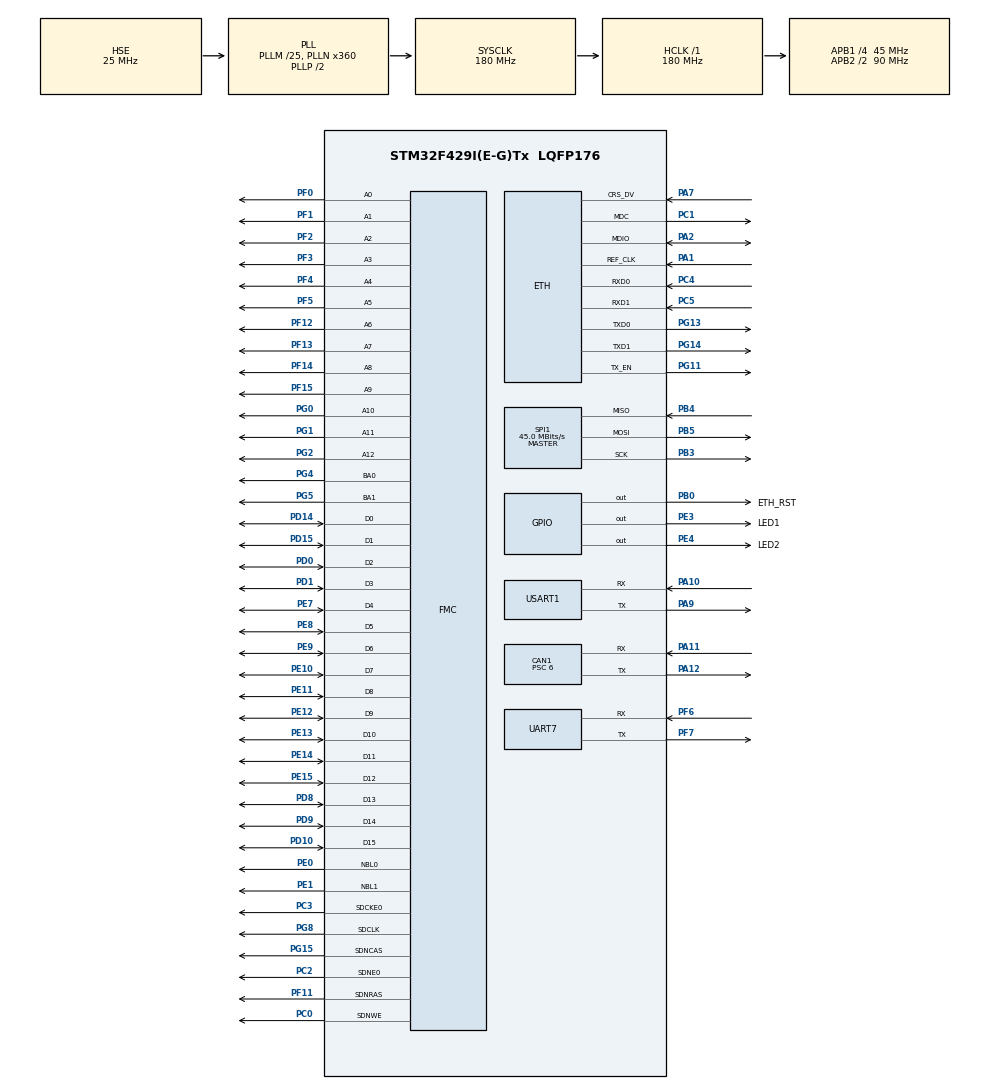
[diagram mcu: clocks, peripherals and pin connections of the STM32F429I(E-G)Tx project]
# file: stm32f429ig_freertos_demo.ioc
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CAN1.BS1=CAN_BS1_9TQ
CAN1.BS2=CAN_BS2_5TQ
CAN1.CalculateTimeQuantum=133.33333333333331
CAN1.NART=ENABLE
CAN1.Prescaler=6
ETH.MediaInterface=ETH_MEDIA_INTERFACE_RMII
ETH.PHY_Name_RMII=userPHY
ETH.PHY_User_Name=LAN8720A
ETH.PhyAddress=0
FMC.CASLatency1=FMC_SDRAM_CAS_LATENCY_3
FMC.ColumnBitsNumber1=FMC_SDRAM_COLUMN_BITS_NUM_9
FMC.ExitSelfRefreshDelay1=7
FMC.LoadToActiveDelay1=2
FMC.RCDDelay1=2
FMC.RPDelay1=2
FMC.ReadBurst1=FMC_SDRAM_RBURST_ENABLE
FMC.ReadPipeDelay1=FMC_SDRAM_RPIPE_DELAY_1
FMC.RowCycleDelay1=7
FMC.SDClockPeriod1=FMC_SDRAM_CLOCK_PERIOD_2
FMC.SelfRefreshTime1=4
FMC.WriteRecoveryTime1=4
FREERTOS.HEAP_NUMBER=5
FREERTOS.Tasks01=defaultTask,0,128,StartDefaultTask,Default,NULL,Dynamic,NULL,NULL
FREERTOS.configTOTAL_HEAP_SIZE=65536
LWIP.GATEWAY_ADDRESS=192.168.000.001
LWIP.IP_ADDRESS=192.168.000.123
LWIP.LWIP_DHCP=0
LWIP.NETMASK_ADDRESS=255.255.255.000
LWIP.Version=v2.1.2_Cube
Mcu.Family=STM32F4
Mcu.Name=STM32F429I(E-G)Tx
Mcu.Package=LQFP176
NVIC.CAN1_RX0_IRQn=true\:5\:0\:false\:false\:true\:true\:true\:true
NVIC.CAN1_RX1_IRQn=true\:5\:0\:false\:false\:true\:true\:true\:true
NVIC.CAN1_SCE_IRQn=true\:5\:0\:false\:false\:true\:true\:true\:true
NVIC.CAN1_TX_IRQn=true\:5\:0\:false\:false\:true\:true\:true\:true
NVIC.ETH_IRQn=true\:5\:0\:false\:false\:true\:true\:false\:true
NVIC.PriorityGroup=NVIC_PRIORITYGROUP_4
NVIC.UART7_IRQn=true\:5\:0\:false\:false\:true\:true\:true\:true
NVIC.USART1_IRQn=true\:5\:0\:false\:false\:true\:true\:true\:true
PA1.Mode=RMII
PA1.Signal=ETH_REF_CLK
PA10.Mode=Asynchronous
PA10.Signal=USART1_RX
PA11.GPIO_PuPd=GPIO_NOPULL
PA11.Mode=Master
PA11.Signal=CAN1_RX
PA12.GPIO_PuPd=GPIO_NOPULL
PA12.Mode=Master
PA12.Signal=CAN1_TX
PA13.Mode=Serial_Wire
PA13.Signal=SYS_JTMS-SWDIO
PA14.Mode=Serial_Wire
PA14.Signal=SYS_JTCK-SWCLK
PA2.Mode=RMII
PA2.Signal=ETH_MDIO
PA7.Mode=RMII
PA7.Signal=ETH_CRS_DV
PA9.Mode=Asynchronous
PA9.Signal=USART1_TX
PB0.GPIO_Label=ETH_RST
PB0.PinState=GPIO_PIN_SET
PB0.Signal=GPIO_Output
PB3.Mode=Full_Duplex_Master
PB3.Signal=SPI1_SCK
PB4.Mode=Full_Duplex_Master
PB4.Signal=SPI1_MISO
PB5.Mode=Full_Duplex_Master
PB5.Signal=SPI1_MOSI
PC0.Signal=FMC_SDNWE
PC1.Mode=RMII
PC1.Signal=ETH_MDC
PC2.Mode=SdramChipSelect1_1
PC2.Signal=FMC_SDNE0
PC3.Mode=SdramChipSelect1_1
PC3.Signal=FMC_SDCKE0
PC4.Mode=RMII
PC4.Signal=ETH_RXD0
PC5.Mode=RMII
PC5.Signal=ETH_RXD1
PD0.Signal=FMC_D2_DA2
PD1.Signal=FMC_D3_DA3
PD10.Signal=FMC_D15_DA15
PD14.Signal=FMC_D0_DA0
PD15.Signal=FMC_D1_DA1
PD8.Signal=FMC_D13_DA13
PD9.Signal=FMC_D14_DA14
PE0.Signal=FMC_NBL0
PE1.Signal=FMC_NBL1
PE10.Signal=FMC_D7_DA7
PE11.Signal=FMC_D8_DA8
PE12.Signal=FMC_D9_DA9
PE13.Signal=FMC_D10_DA10
PE14.Signal=FMC_D11_DA11
PE15.Signal=FMC_D12_DA12
PE3.GPIO_Label=LED1
PE3.Signal=GPIO_Output
PE4.GPIO_Label=LED2
PE4.Signal=GPIO_Output
PE7.Signal=FMC_D4_DA4
PE8.Signal=FMC_D5_DA5
PE9.Signal=FMC_D6_DA6
PF0.Signal=FMC_A0
PF1.Signal=FMC_A1
PF11.Signal=FMC_SDNRAS
PF12.Signal=FMC_A6
PF13.Signal=FMC_A7
PF14.Signal=FMC_A8
PF15.Signal=FMC_A9
PF2.Signal=FMC_A2
PF3.Signal=FMC_A3
PF4.Signal=FMC_A4
PF5.Signal=FMC_A5
PF6.Mode=Asynchronous
PF6.Signal=UART7_RX
PF7.Mode=Asynchronous
PF7.Signal=UART7_TX
PG0.Signal=FMC_A10
PG1.Signal=FMC_A11
PG11.Mode=RMII
PG11.Signal=ETH_TX_EN
PG13.Mode=RMII
PG13.Signal=ETH_TXD0
PG14.Mode=RMII
PG14.Signal=ETH_TXD1
PG15.Signal=FMC_SDNCAS
PG2.Signal=FMC_A12
PG4.Signal=FMC_A14_BA0
PG5.Signal=FMC_A15_BA1
PG8.Signal=FMC_SDCLK
PH0/OSC_IN.Mode=HSE-External-Oscillator
PH0/OSC_IN.Signal=RCC_OSC_IN
PH1/OSC_OUT.Mode=HSE-External-Oscillator
PH1/OSC_OUT.Signal=RCC_OSC_OUT
ProjectManager.HeapSize=0x800
ProjectManager.StackSize=0x800
ProjectManager.TargetToolchain=STM32CubeIDE
RCC.48MHZClocksFreq_Value=90000000
RCC.AHBFreq_Value=180000000
RCC.APB1CLKDivider=RCC_HCLK_DIV4
RCC.APB1Freq_Value=45000000
RCC.APB1TimFreq_Value=90000000
RCC.APB2CLKDivider=RCC_HCLK_DIV2
RCC.APB2Freq_Value=90000000
RCC.APB2TimFreq_Value=180000000
RCC.CortexFreq_Value=180000000
RCC.HCLKFreq_Value=180000000
RCC.HSE_VALUE=25000000
RCC.HSI_VALUE=16000000
RCC.LSE_VALUE=32768
RCC.PLLM=25
RCC.PLLN=360
RCC.PLLSourceVirtual=RCC_PLLSOURCE_HSE
RCC.SYSCLKFreq_VALUE=180000000
RCC.SYSCLKSource=RCC_SYSCLKSOURCE_PLLCLK
RCC.VCOOutputFreq_Value=360000000
SH.FMC_A0.0=FMC_A0,13b-sda1
SH.FMC_A1.0=FMC_A1,13b-sda1
SH.FMC_A10.0=FMC_A10,13b-sda1
SH.FMC_A11.0=FMC_A11,13b-sda1
SH.FMC_A12.0=FMC_A12,13b-sda1
SH.FMC_A14_BA0.0=FMC_BA0,FourSdramBanks1
SH.FMC_A15_BA1.0=FMC_BA1,FourSdramBanks1
SH.FMC_A2.0=FMC_A2,13b-sda1
SH.FMC_A3.0=FMC_A3,13b-sda1
SH.FMC_A4.0=FMC_A4,13b-sda1
SH.FMC_A5.0=FMC_A5,13b-sda1
SH.FMC_A6.0=FMC_A6,13b-sda1
SH.FMC_A7.0=FMC_A7,13b-sda1
SH.FMC_A8.0=FMC_A8,13b-sda1
SH.FMC_A9.0=FMC_A9,13b-sda1
SH.FMC_D0_DA0.0=FMC_D0,sd-16b-d1
SH.FMC_D10_DA10.0=FMC_D10,sd-16b-d1
SH.FMC_D11_DA11.0=FMC_D11,sd-16b-d1
SH.FMC_D12_DA12.0=FMC_D12,sd-16b-d1
SH.FMC_D13_DA13.0=FMC_D13,sd-16b-d1
SH.FMC_D14_DA14.0=FMC_D14,sd-16b-d1
SH.FMC_D15_DA15.0=FMC_D15,sd-16b-d1
SH.FMC_D1_DA1.0=FMC_D1,sd-16b-d1
SH.FMC_D2_DA2.0=FMC_D2,sd-16b-d1
SH.FMC_D3_DA3.0=FMC_D3,sd-16b-d1
SH.FMC_D4_DA4.0=FMC_D4,sd-16b-d1
SH.FMC_D5_DA5.0=FMC_D5,sd-16b-d1
SH.FMC_D6_DA6.0=FMC_D6,sd-16b-d1
SH.FMC_D7_DA7.0=FMC_D7,sd-16b-d1
SH.FMC_D8_DA8.0=FMC_D8,sd-16b-d1
SH.FMC_D9_DA9.0=FMC_D9,sd-16b-d1
SH.FMC_NBL0.0=FMC_NBL0,Sd2ByteEnable1
SH.FMC_NBL1.0=FMC_NBL1,Sd2ByteEnable1
SH.FMC_SDCLK.0=FMC_SDCLK,13b-sda1
SH.FMC_SDNCAS.0=FMC_SDNCAS,13b-sda1
SH.FMC_SDNRAS.0=FMC_SDNRAS,13b-sda1
SH.FMC_SDNWE.0=FMC_SDNWE,13b-sda1
SPI1.CalculateBaudRate=45.0 MBits/s
SPI1.Direction=SPI_DIRECTION_2LINES
SPI1.Mode=SPI_MODE_MASTER
SPI1.VirtualType=VM_MASTER
UART7.VirtualMode=Asynchronous
USART1.VirtualMode=VM_ASYNC
VP_FREERTOS_VS_CMSIS_V1.Mode=CMSIS_V1
VP_LWIP_VS_Enabled.Mode=Enabled
board=custom

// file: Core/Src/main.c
/* USER CODE BEGIN Header */
/**
  ******************************************************************************
  * @file           : main.c
  * @brief          : Main program body
  ******************************************************************************
  * @attention
  *
  * <h2><center>&copy; Copyright (c) 2020 STMicroelectronics.
  * All rights reserved.</center></h2>
  *
  * This software component is licensed by ST under Ultimate Liberty license
  * SLA0044, the "License"; You may not use this file except in compliance with
  * the License. You may obtain a copy of the License at:
  *                             www.st.com/SLA0044
  *
  ******************************************************************************
  */
/* USER CODE END Header */

#include "main.h"
#include "cmsis_os.h"
#include "can.h"
#include "lwip.h"
#include "spi.h"
#include "usart.h"
#include "gpio.h"
#include "fmc.h"

void SystemClock_Config(void);
void MX_FREERTOS_Init(void);

int main(void)
{

  /* MCU Configuration--------------------------------------------------------*/

  /* Reset of all peripherals, Initializes the Flash interface and the Systick. */
  HAL_Init();

  /* Configure the system clock */
  SystemClock_Config();

  /* Initialize all configured peripherals */
  MX_GPIO_Init();
  MX_CAN1_Init();
  MX_UART7_Init();
  MX_USART1_UART_Init();
  MX_FMC_Init();
  MX_SPI1_Init();
  /* USER CODE BEGIN 2 */
  SDRAM_Init();
  heap_init();
  /* USER CODE END 2 */

  /* Call init function for freertos objects (in freertos.c) */
  MX_FREERTOS_Init();
  /* Start scheduler */
  osKernelStart();

  /* We should never get here as control is now taken by the scheduler */
  /* Infinite loop */
  while (1)
  {

  }
}

void SystemClock_Config(void)
{
  RCC_OscInitTypeDef RCC_OscInitStruct = {0};
  RCC_ClkInitTypeDef RCC_ClkInitStruct = {0};

  /** Configure the main internal regulator output voltage
  */
  __HAL_RCC_PWR_CLK_ENABLE();
  __HAL_PWR_VOLTAGESCALING_CONFIG(PWR_REGULATOR_VOLTAGE_SCALE1);
  /** Initializes the CPU, AHB and APB busses clocks
  */
  RCC_OscInitStruct.OscillatorType = RCC_OSCILLATORTYPE_HSE;
  RCC_OscInitStruct.HSEState = RCC_HSE_ON;
  RCC_OscInitStruct.PLL.PLLState = RCC_PLL_ON;
  RCC_OscInitStruct.PLL.PLLSource = RCC_PLLSOURCE_HSE;
  RCC_OscInitStruct.PLL.PLLM = 25;
  RCC_OscInitStruct.PLL.PLLN = 360;
  RCC_OscInitStruct.PLL.PLLP = RCC_PLLP_DIV2;
  RCC_OscInitStruct.PLL.PLLQ = 4;
  if (HAL_RCC_OscConfig(&RCC_OscInitStruct) != HAL_OK)
  {
    Error_Handler();
  }
  /** Activate the Over-Drive mode
  */
  if (HAL_PWREx_EnableOverDrive() != HAL_OK)
  {
    Error_Handler();
  }
  /** Initializes the CPU, AHB and APB busses clocks
  */
  RCC_ClkInitStruct.ClockType = RCC_CLOCKTYPE_HCLK|RCC_CLOCKTYPE_SYSCLK
                              |RCC_CLOCKTYPE_PCLK1|RCC_CLOCKTYPE_PCLK2;
  RCC_ClkInitStruct.SYSCLKSource = RCC_SYSCLKSOURCE_PLLCLK;
  RCC_ClkInitStruct.AHBCLKDivider = RCC_SYSCLK_DIV1;
  RCC_ClkInitStruct.APB1CLKDivider = RCC_HCLK_DIV4;
  RCC_ClkInitStruct.APB2CLKDivider = RCC_HCLK_DIV2;

  if (HAL_RCC_ClockConfig(&RCC_ClkInitStruct, FLASH_LATENCY_5) != HAL_OK)
  {
    Error_Handler();
  }
}

void Error_Handler(void)
{
}

/************************ (C) COPYRIGHT STMicroelectronics *****END OF FILE****/

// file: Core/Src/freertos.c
/* USER CODE BEGIN Header */
/**
  ******************************************************************************
  * File Name          : freertos.c
  * Description        : Code for freertos applications
  ******************************************************************************
  * @attention
  *
  * <h2><center>&copy; Copyright (c) 2020 STMicroelectronics.
  * All rights reserved.</center></h2>
  *
  * This software component is licensed by ST under Ultimate Liberty license
  * SLA0044, the "License"; You may not use this file except in compliance with
  * the License. You may obtain a copy of the License at:
  *                             www.st.com/SLA0044
  *
  ******************************************************************************
  */
/* USER CODE END Header */

#include "FreeRTOS.h"
#include "task.h"
#include "main.h"
#include "cmsis_os.h"

osThreadId defaultTaskHandle;

void StartDefaultTask(void const * argument);

extern void MX_LWIP_Init(void);
void MX_FREERTOS_Init(void); /* (MISRA C 2004 rule 8.1) */

/* GetIdleTaskMemory prototype (linked to static allocation support) */
void vApplicationGetIdleTaskMemory( StaticTask_t **ppxIdleTaskTCBBuffer, StackType_t **ppxIdleTaskStackBuffer, uint32_t *pulIdleTaskStackSize );

/* USER CODE BEGIN GET_IDLE_TASK_MEMORY */
static StaticTask_t xIdleTaskTCBBuffer;
static StackType_t xIdleStack[configMINIMAL_STACK_SIZE];

void vApplicationGetIdleTaskMemory( StaticTask_t **ppxIdleTaskTCBBuffer, StackType_t **ppxIdleTaskStackBuffer, uint32_t *pulIdleTaskStackSize )
{
  *ppxIdleTaskTCBBuffer = &xIdleTaskTCBBuffer;
  *ppxIdleTaskStackBuffer = &xIdleStack[0];
  *pulIdleTaskStackSize = configMINIMAL_STACK_SIZE;
  /* place for user code */
}
/* USER CODE END GET_IDLE_TASK_MEMORY */

void MX_FREERTOS_Init(void) {

  /* Create the thread(s) */
  /* definition and creation of defaultTask */
  osThreadDef(defaultTask, StartDefaultTask, osPriorityNormal, 0, 128);
  defaultTaskHandle = osThreadCreate(osThread(defaultTask), NULL);

}

void StartDefaultTask(void const * argument)
{
  /* init code for LWIP */
  MX_LWIP_Init();
  /* USER CODE BEGIN StartDefaultTask */
  int shell_thread_entry(void);
  int canopen_application_entry(void);
  shell_thread_entry();
  canopen_application_entry();
  /* Infinite loop */
  for(;;)
  {
	HAL_GPIO_TogglePin(GPIOE, LED1_Pin|LED2_Pin);
    osDelay(500);
  }
  /* USER CODE END StartDefaultTask */
}

/************************ (C) COPYRIGHT STMicroelectronics *****END OF FILE****/
